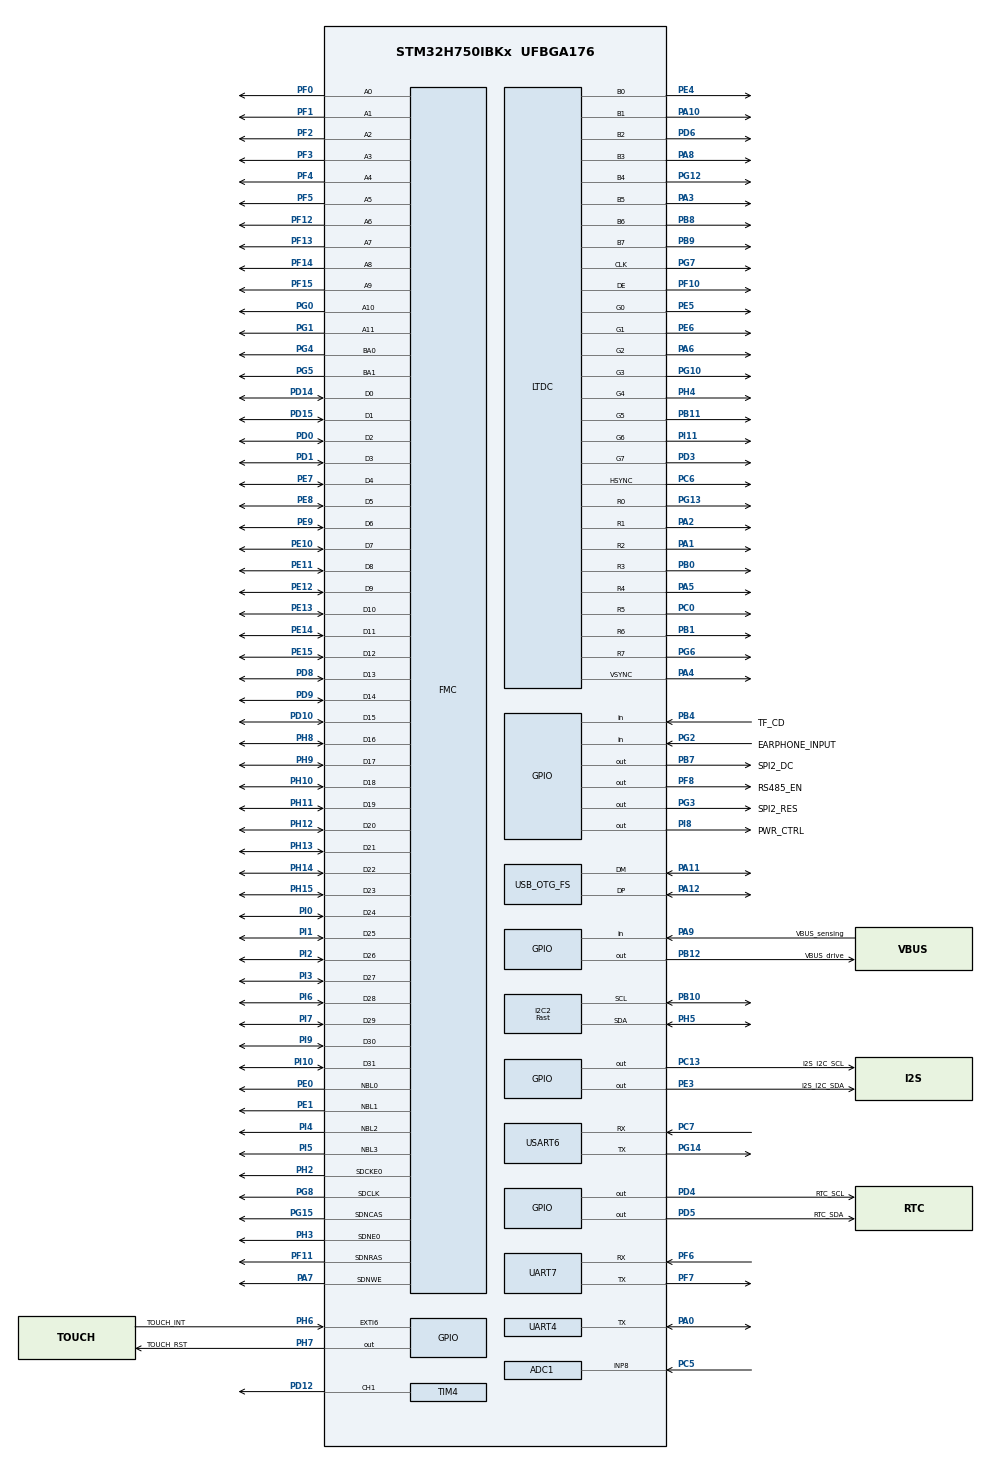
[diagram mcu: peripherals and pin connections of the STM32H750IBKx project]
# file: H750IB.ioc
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ADC1.Channel-3\#ChannelRegularConversion=ADC_CHANNEL_8
ADC1.ClockPrescaler=ADC_CLOCK_ASYNC_DIV8
ADC1.ContinuousConvMode=ENABLE
ADC1.ConversionDataManagement=ADC_CONVERSIONDATA_DMA_CIRCULAR
ADC1.ExternalTrigConv=ADC_EXTERNALTRIG_T15_TRGO
ADC1.NbrOfConversionFlag=1
ADC1.OffsetNumber-3\#ChannelRegularConversion=ADC_OFFSET_NONE
ADC1.OffsetSignedSaturation-3\#ChannelRegularConversion=DISABLE
ADC1.Overrun=ADC_OVR_DATA_OVERWRITTEN
ADC1.Rank-3\#ChannelRegularConversion=1
ADC1.SamplingTime-3\#ChannelRegularConversion=ADC_SAMPLETIME_387CYCLES_5
ADC1.master=1
ADC3.Channel-0\#ChannelRegularConversion=ADC_CHANNEL_TEMPSENSOR
ADC3.ClockPrescaler=ADC_CLOCK_ASYNC_DIV8
ADC3.ClockPrescalerADC3=ADC_CLOCK_ASYNC_DIV128
ADC3.ContinuousConvMode=ENABLE
ADC3.ConversionDataManagement=ADC_CONVERSIONDATA_DMA_CIRCULAR
ADC3.ExternalTrigConv=ADC_EXTERNALTRIG_T15_TRGO
ADC3.NbrOfConversionFlag=1
ADC3.OffsetNumber-0\#ChannelRegularConversion=ADC_OFFSET_NONE
ADC3.OffsetSignedSaturation-0\#ChannelRegularConversion=DISABLE
ADC3.Overrun=ADC_OVR_DATA_OVERWRITTEN
ADC3.Rank-0\#ChannelRegularConversion=1
ADC3.SamplingTime-0\#ChannelRegularConversion=ADC_SAMPLETIME_64CYCLES_5
CORTEX_M7.AccessPermission_S-Cortex_Memory_Protection_Unit_Region1_Settings_S=MPU_REGION_FULL_ACCESS
CORTEX_M7.AccessPermission_Spec=MPU_REGION_FULL_ACCESS
CORTEX_M7.BaseAddress_S-Cortex_Memory_Protection_Unit_Region1_Settings_S=0x24000000
CORTEX_M7.BaseAddress_Spec=0x70000000
CORTEX_M7.CPU_DCache=Enabled
CORTEX_M7.CPU_ICache=Enabled
CORTEX_M7.DisableExec_Spec=MPU_INSTRUCTION_ACCESS_ENABLE
CORTEX_M7.Enable_S-Cortex_Memory_Protection_Unit_Region1_Settings_S=MPU_REGION_ENABLE
CORTEX_M7.IsCacheable_S-Cortex_Memory_Protection_Unit_Region1_Settings_S=MPU_ACCESS_CACHEABLE
CORTEX_M7.IsCacheable_Spec=MPU_ACCESS_CACHEABLE
CORTEX_M7.IsShareable_Spec=MPU_ACCESS_NOT_SHAREABLE
CORTEX_M7.Size_S-Cortex_Memory_Protection_Unit_Region1_Settings_S=MPU_REGION_SIZE_1MB
CORTEX_M7.Size_Spec=MPU_REGION_SIZE_256MB
CORTEX_M7.SubRegionDisable_S-Cortex_Memory_Protection_Unit_Region1_Settings_S=0x00
CORTEX_M7.SubRegionDisable_Spec=0x00
CORTEX_M7.default_mode_Activation=1
DMA2D.ColorMode=DMA2D_OUTPUT_RGB565
Dma.ADC1.5.Direction=DMA_PERIPH_TO_MEMORY
Dma.ADC1.5.EventEnable=DISABLE
Dma.ADC1.5.FIFOMode=DMA_FIFOMODE_DISABLE
Dma.ADC1.5.Instance=DMA1_Stream5
Dma.ADC1.5.MemDataAlignment=DMA_MDATAALIGN_HALFWORD
Dma.ADC1.5.MemInc=DMA_MINC_ENABLE
Dma.ADC1.5.Mode=DMA_CIRCULAR
Dma.ADC1.5.PeriphDataAlignment=DMA_PDATAALIGN_HALFWORD
Dma.ADC1.5.PeriphInc=DMA_PINC_DISABLE
Dma.ADC1.5.Polarity=HAL_DMAMUX_REQ_GEN_RISING
Dma.ADC1.5.Priority=DMA_PRIORITY_LOW
Dma.ADC1.5.RequestNumber=1
Dma.ADC1.5.SignalID=NONE
Dma.ADC1.5.SyncEnable=DISABLE
Dma.ADC1.5.SyncPolarity=HAL_DMAMUX_SYNC_NO_EVENT
Dma.ADC1.5.SyncRequestNumber=1
Dma.ADC1.5.SyncSignalID=NONE
Dma.ADC3.4.Direction=DMA_PERIPH_TO_MEMORY
Dma.ADC3.4.EventEnable=DISABLE
Dma.ADC3.4.FIFOMode=DMA_FIFOMODE_DISABLE
Dma.ADC3.4.Instance=DMA1_Stream0
Dma.ADC3.4.MemDataAlignment=DMA_MDATAALIGN_HALFWORD
Dma.ADC3.4.MemInc=DMA_MINC_ENABLE
Dma.ADC3.4.Mode=DMA_CIRCULAR
Dma.ADC3.4.PeriphDataAlignment=DMA_PDATAALIGN_HALFWORD
Dma.ADC3.4.PeriphInc=DMA_PINC_DISABLE
Dma.ADC3.4.Polarity=HAL_DMAMUX_REQ_GEN_RISING
Dma.ADC3.4.Priority=DMA_PRIORITY_LOW
Dma.ADC3.4.RequestNumber=1
Dma.ADC3.4.SignalID=NONE
Dma.ADC3.4.SyncEnable=DISABLE
Dma.ADC3.4.SyncPolarity=HAL_DMAMUX_SYNC_NO_EVENT
Dma.ADC3.4.SyncRequestNumber=1
Dma.ADC3.4.SyncSignalID=NONE
Dma.Request0=UART4_TX
Dma.Request1=UART4_RX
Dma.Request2=UART7_RX
Dma.Request3=UART7_TX
Dma.Request4=ADC3
Dma.Request5=ADC1
Dma.Request6=USART6_RX
Dma.Request7=USART6_TX
Dma.UART4_RX.1.Direction=DMA_PERIPH_TO_MEMORY
Dma.UART4_RX.1.EventEnable=DISABLE
Dma.UART4_RX.1.FIFOMode=DMA_FIFOMODE_DISABLE
Dma.UART4_RX.1.Instance=DMA1_Stream1
Dma.UART4_RX.1.MemDataAlignment=DMA_MDATAALIGN_BYTE
Dma.UART4_RX.1.MemInc=DMA_MINC_ENABLE
Dma.UART4_RX.1.Mode=DMA_NORMAL
Dma.UART4_RX.1.PeriphDataAlignment=DMA_PDATAALIGN_BYTE
Dma.UART4_RX.1.PeriphInc=DMA_PINC_DISABLE
Dma.UART4_RX.1.Polarity=HAL_DMAMUX_REQ_GEN_RISING
Dma.UART4_RX.1.Priority=DMA_PRIORITY_LOW
Dma.UART4_RX.1.RequestNumber=1
Dma.UART4_RX.1.SignalID=NONE
Dma.UART4_RX.1.SyncEnable=DISABLE
Dma.UART4_RX.1.SyncPolarity=HAL_DMAMUX_SYNC_NO_EVENT
Dma.UART4_RX.1.SyncRequestNumber=1
Dma.UART4_RX.1.SyncSignalID=NONE
Dma.UART4_TX.0.Direction=DMA_MEMORY_TO_PERIPH
Dma.UART4_TX.0.EventEnable=DISABLE
Dma.UART4_TX.0.FIFOMode=DMA_FIFOMODE_DISABLE
Dma.UART4_TX.0.Instance=DMA1_Stream4
Dma.UART4_TX.0.MemDataAlignment=DMA_MDATAALIGN_BYTE
Dma.UART4_TX.0.MemInc=DMA_MINC_ENABLE
Dma.UART4_TX.0.Mode=DMA_NORMAL
Dma.UART4_TX.0.PeriphDataAlignment=DMA_PDATAALIGN_BYTE
Dma.UART4_TX.0.PeriphInc=DMA_PINC_DISABLE
Dma.UART4_TX.0.Polarity=HAL_DMAMUX_REQ_GEN_RISING
Dma.UART4_TX.0.Priority=DMA_PRIORITY_LOW
Dma.UART4_TX.0.RequestNumber=1
Dma.UART4_TX.0.SignalID=NONE
Dma.UART4_TX.0.SyncEnable=DISABLE
Dma.UART4_TX.0.SyncPolarity=HAL_DMAMUX_SYNC_NO_EVENT
Dma.UART4_TX.0.SyncRequestNumber=1
Dma.UART4_TX.0.SyncSignalID=NONE
Dma.UART7_RX.2.Direction=DMA_PERIPH_TO_MEMORY
Dma.UART7_RX.2.EventEnable=DISABLE
Dma.UART7_RX.2.FIFOMode=DMA_FIFOMODE_DISABLE
Dma.UART7_RX.2.Instance=DMA1_Stream2
Dma.UART7_RX.2.MemDataAlignment=DMA_MDATAALIGN_BYTE
Dma.UART7_RX.2.MemInc=DMA_MINC_ENABLE
Dma.UART7_RX.2.Mode=DMA_NORMAL
Dma.UART7_RX.2.PeriphDataAlignment=DMA_PDATAALIGN_BYTE
Dma.UART7_RX.2.PeriphInc=DMA_PINC_DISABLE
Dma.UART7_RX.2.Polarity=HAL_DMAMUX_REQ_GEN_RISING
Dma.UART7_RX.2.Priority=DMA_PRIORITY_LOW
Dma.UART7_RX.2.RequestNumber=1
Dma.UART7_RX.2.SignalID=NONE
Dma.UART7_RX.2.SyncEnable=DISABLE
Dma.UART7_RX.2.SyncPolarity=HAL_DMAMUX_SYNC_NO_EVENT
Dma.UART7_RX.2.SyncRequestNumber=1
Dma.UART7_RX.2.SyncSignalID=NONE
Dma.UART7_TX.3.Direction=DMA_MEMORY_TO_PERIPH
Dma.UART7_TX.3.EventEnable=DISABLE
Dma.UART7_TX.3.FIFOMode=DMA_FIFOMODE_DISABLE
Dma.UART7_TX.3.Instance=DMA1_Stream3
Dma.UART7_TX.3.MemDataAlignment=DMA_MDATAALIGN_BYTE
Dma.UART7_TX.3.MemInc=DMA_MINC_ENABLE
Dma.UART7_TX.3.Mode=DMA_NORMAL
Dma.UART7_TX.3.PeriphDataAlignment=DMA_PDATAALIGN_BYTE
Dma.UART7_TX.3.PeriphInc=DMA_PINC_DISABLE
Dma.UART7_TX.3.Polarity=HAL_DMAMUX_REQ_GEN_RISING
Dma.UART7_TX.3.Priority=DMA_PRIORITY_LOW
Dma.UART7_TX.3.RequestNumber=1
Dma.UART7_TX.3.SignalID=NONE
Dma.UART7_TX.3.SyncEnable=DISABLE
Dma.UART7_TX.3.SyncPolarity=HAL_DMAMUX_SYNC_NO_EVENT
Dma.UART7_TX.3.SyncRequestNumber=1
Dma.UART7_TX.3.SyncSignalID=NONE
Dma.USART6_RX.6.Direction=DMA_PERIPH_TO_MEMORY
Dma.USART6_RX.6.EventEnable=DISABLE
Dma.USART6_RX.6.FIFOMode=DMA_FIFOMODE_DISABLE
Dma.USART6_RX.6.Instance=DMA1_Stream6
Dma.USART6_RX.6.MemDataAlignment=DMA_MDATAALIGN_BYTE
Dma.USART6_RX.6.MemInc=DMA_MINC_ENABLE
Dma.USART6_RX.6.Mode=DMA_CIRCULAR
Dma.USART6_RX.6.PeriphDataAlignment=DMA_PDATAALIGN_BYTE
Dma.USART6_RX.6.PeriphInc=DMA_PINC_DISABLE
Dma.USART6_RX.6.Polarity=HAL_DMAMUX_REQ_GEN_RISING
Dma.USART6_RX.6.Priority=DMA_PRIORITY_LOW
Dma.USART6_RX.6.RequestNumber=1
Dma.USART6_RX.6.SignalID=NONE
Dma.USART6_RX.6.SyncEnable=DISABLE
Dma.USART6_RX.6.SyncPolarity=HAL_DMAMUX_SYNC_NO_EVENT
Dma.USART6_RX.6.SyncRequestNumber=1
Dma.USART6_RX.6.SyncSignalID=NONE
Dma.USART6_TX.7.Direction=DMA_MEMORY_TO_PERIPH
Dma.USART6_TX.7.EventEnable=DISABLE
Dma.USART6_TX.7.FIFOMode=DMA_FIFOMODE_DISABLE
Dma.USART6_TX.7.Instance=DMA1_Stream7
Dma.USART6_TX.7.MemDataAlignment=DMA_MDATAALIGN_BYTE
Dma.USART6_TX.7.MemInc=DMA_MINC_ENABLE
Dma.USART6_TX.7.Mode=DMA_NORMAL
Dma.USART6_TX.7.PeriphDataAlignment=DMA_PDATAALIGN_BYTE
Dma.USART6_TX.7.PeriphInc=DMA_PINC_DISABLE
Dma.USART6_TX.7.Polarity=HAL_DMAMUX_REQ_GEN_RISING
Dma.USART6_TX.7.Priority=DMA_PRIORITY_LOW
Dma.USART6_TX.7.RequestNumber=1
Dma.USART6_TX.7.SignalID=NONE
Dma.USART6_TX.7.SyncEnable=DISABLE
Dma.USART6_TX.7.SyncPolarity=HAL_DMAMUX_SYNC_NO_EVENT
Dma.USART6_TX.7.SyncRequestNumber=1
Dma.USART6_TX.7.SyncSignalID=NONE
FMC.CASLatency1=FMC_SDRAM_CAS_LATENCY_3
FMC.ColumnBitsNumber1=FMC_SDRAM_COLUMN_BITS_NUM_9
FMC.ExitSelfRefreshDelay1=7
FMC.LoadToActiveDelay1=2
FMC.RCDDelay1=2
FMC.RPDelay1=2
FMC.RPDelay2=2
FMC.ReadBurst1=FMC_SDRAM_RBURST_ENABLE
FMC.ReadBurst2=FMC_SDRAM_RBURST_ENABLE
FMC.ReadPipeDelay1=FMC_SDRAM_RPIPE_DELAY_1
FMC.ReadPipeDelay2=FMC_SDRAM_RPIPE_DELAY_1
FMC.RowCycleDelay1=7
FMC.RowCycleDelay2=7
FMC.SDClockPeriod1=FMC_SDRAM_CLOCK_PERIOD_2
FMC.SDClockPeriod2=FMC_SDRAM_CLOCK_PERIOD_2
FMC.SelfRefreshTime1=4
FMC.WriteRecoveryTime1=3
I2C2.I2C_Speed_Mode=I2C_Fast
I2C2.Timing=0x00B03FDB
LTDC.ActiveH=600
LTDC.ActiveW=1024
LTDC.Alpha_L0=255
LTDC.FBStartAdress_L0=0x70000000
LTDC.HBP=140
LTDC.HFP=160
LTDC.HSync=20
LTDC.ImageHeight_L0=600
LTDC.ImageWidth_L0=1024
LTDC.Layers=0
LTDC.PixelFormat_L0=LTDC_PIXEL_FORMAT_RGB888
LTDC.VBP=20
LTDC.VFP=12
LTDC.VSync=3
LTDC.WindowX1_L0=1024
LTDC.WindowY1_L0=600
Mcu.Family=STM32H7
Mcu.Name=STM32H750IBKx
Mcu.Package=UFBGA176
Mcu.UserConstants=SysTemp_TIM,$$_TIM15_IP_HANDLE_$$;VBAT_ADC,$$_ADC1_IP_HANDLE_$$;ESP_UART,$$_USART6_IP_HANDLE_$$
NVIC.DMA1_Stream0_IRQn=true\:0\:0\:false\:false\:true\:false\:true\:true
NVIC.DMA1_Stream1_IRQn=true\:0\:0\:false\:false\:true\:false\:true\:true
NVIC.DMA1_Stream2_IRQn=true\:0\:0\:false\:false\:true\:false\:true\:true
NVIC.DMA1_Stream3_IRQn=true\:0\:0\:false\:false\:true\:false\:true\:true
NVIC.DMA1_Stream4_IRQn=true\:0\:0\:false\:false\:true\:false\:true\:true
NVIC.DMA1_Stream5_IRQn=true\:0\:0\:false\:false\:true\:false\:true\:true
NVIC.DMA1_Stream6_IRQn=true\:0\:0\:false\:false\:true\:false\:true\:true
NVIC.DMA1_Stream7_IRQn=true\:0\:0\:false\:false\:true\:false\:true\:true
NVIC.EXTI9_5_IRQn=true\:0\:0\:false\:false\:true\:true\:true\:true
NVIC.I2C2_ER_IRQn=true\:0\:0\:false\:false\:true\:true\:true\:true
NVIC.I2C2_EV_IRQn=true\:0\:0\:false\:false\:true\:true\:true\:true
NVIC.OTG_FS_IRQn=true\:0\:0\:false\:false\:true\:false\:true\:true
NVIC.PriorityGroup=NVIC_PRIORITYGROUP_4
NVIC.TIM8_TRG_COM_TIM14_IRQn=true\:0\:0\:false\:false\:true\:true\:true\:true
NVIC.UART4_IRQn=true\:0\:0\:false\:false\:true\:true\:true\:true
NVIC.UART7_IRQn=true\:0\:0\:false\:false\:true\:true\:true\:true
NVIC.USART6_IRQn=true\:0\:0\:false\:false\:true\:true\:true\:true
PA0.GPIO_PuPd=GPIO_PULLUP
PA0.Mode=Half_duplex(single_wire_mode)
PA0.Signal=UART4_TX
PA1.GPIO_Speed=GPIO_SPEED_FREQ_HIGH
PA1.Mode=RGB888
PA1.Signal=LTDC_R2
PA10.GPIO_Speed=GPIO_SPEED_FREQ_HIGH
PA10.Mode=RGB888
PA10.Signal=LTDC_B1
PA11.Mode=Device_Only
PA11.Signal=USB_OTG_FS_DM
PA12.Mode=Device_Only
PA12.Signal=USB_OTG_FS_DP
PA13\ (JTMS/SWDIO).Mode=Serial_Wire
PA13\ (JTMS/SWDIO).Signal=DEBUG_JTMS-SWDIO
PA14\ (JTCK/SWCLK).Mode=Serial_Wire
PA14\ (JTCK/SWCLK).Signal=DEBUG_JTCK-SWCLK
PA2.GPIO_Speed=GPIO_SPEED_FREQ_HIGH
PA2.Mode=RGB888
PA2.Signal=LTDC_R1
PA3.GPIO_Speed=GPIO_SPEED_FREQ_HIGH
PA3.Mode=RGB888
PA3.Signal=LTDC_B5
PA4.GPIO_Speed=GPIO_SPEED_FREQ_HIGH
PA4.Mode=RGB888
PA4.Signal=LTDC_VSYNC
PA5.GPIO_Speed=GPIO_SPEED_FREQ_HIGH
PA5.Mode=RGB888
PA5.Signal=LTDC_R4
PA6.GPIO_Speed=GPIO_SPEED_FREQ_HIGH
PA6.Mode=RGB888
PA6.Signal=LTDC_G2
PA7.Signal=FMC_SDNWE
PA8.GPIO_Speed=GPIO_SPEED_FREQ_HIGH
PA8.Mode=RGB888
PA8.Signal=LTDC_B3
PA9.GPIO_Label=VBUS_sensing
PA9.Signal=GPIO_Input
PB0.GPIO_Speed=GPIO_SPEED_FREQ_HIGH
PB0.Mode=RGB888
PB0.Signal=LTDC_R3
PB1.GPIO_Speed=GPIO_SPEED_FREQ_HIGH
PB1.Mode=RGB888
PB1.Signal=LTDC_R6
PB10.GPIO_Pu=GPIO_PULLUP
PB10.Mode=I2C
PB10.Signal=I2C2_SCL
PB11.GPIO_Speed=GPIO_SPEED_FREQ_HIGH
PB11.Mode=RGB888
PB11.Signal=LTDC_G5
PB12.GPIO_Label=VBUS_drive
PB12.Signal=GPIO_Output
PB4\ (NJTRST).GPIO_Label=TF_CD
PB4\ (NJTRST).Signal=GPIO_Input
PB7.GPIO_Label=SPI2_DC
PB7.Signal=GPIO_Output
PB8.GPIO_Speed=GPIO_SPEED_FREQ_HIGH
PB8.Mode=RGB888
PB8.Signal=LTDC_B6
PB9.GPIO_Speed=GPIO_SPEED_FREQ_HIGH
PB9.Mode=RGB888
PB9.Signal=LTDC_B7
PC0.GPIO_Speed=GPIO_SPEED_FREQ_HIGH
PC0.Mode=RGB888
PC0.Signal=LTDC_R5
PC13.GPIO_Label=I2S_I2C_SCL
PC13.Signal=GPIO_Output
PC14-OSC32_IN\ (OSC32_IN).Mode=LSE-External-Oscillator
PC14-OSC32_IN\ (OSC32_IN).Signal=RCC_OSC32_IN
PC15-OSC32_OUT\ (OSC32_OUT).Mode=LSE-External-Oscillator
PC15-OSC32_OUT\ (OSC32_OUT).Signal=RCC_OSC32_OUT
PC5.Signal=ADCx_INP8
PC6.GPIO_Speed=GPIO_SPEED_FREQ_HIGH
PC6.Mode=RGB888
PC6.Signal=LTDC_HSYNC
PC7.Mode=Asynchronous
PC7.Signal=USART6_RX
PD0.Signal=FMC_D2_DA2
PD1.Signal=FMC_D3_DA3
PD10.Signal=FMC_D15_DA15
PD12.GPIO_ModeDefaultPP=GPIO_MODE_AF_PP
PD12.GPIO_PuPd=GPIO_NOPULL
PD12.GPIO_Speed=GPIO_SPEED_FREQ_LOW
PD12.Signal=S_TIM4_CH1
PD14.Signal=FMC_D0_DA0
PD15.Signal=FMC_D1_DA1
PD3.GPIO_Speed=GPIO_SPEED_FREQ_HIGH
PD3.Mode=RGB888
PD3.Signal=LTDC_G7
PD4.GPIO_Label=RTC_SCL
PD4.GPIO_ModeDefaultOutputPP=GPIO_MODE_OUTPUT_OD
PD4.GPIO_PuPd=GPIO_NOPULL
PD4.Signal=GPIO_Output
PD5.GPIO_Label=RTC_SDA
PD5.GPIO_ModeDefaultOutputPP=GPIO_MODE_OUTPUT_OD
PD5.GPIO_PuPd=GPIO_NOPULL
PD5.Signal=GPIO_Output
PD6.GPIO_Speed=GPIO_SPEED_FREQ_HIGH
PD6.Mode=RGB888
PD6.Signal=LTDC_B2
PD8.Signal=FMC_D13_DA13
PD9.Signal=FMC_D14_DA14
PE0.Signal=FMC_NBL0
PE1.Signal=FMC_NBL1
PE10.Signal=FMC_D7_DA7
PE11.Signal=FMC_D8_DA8
PE12.Signal=FMC_D9_DA9
PE13.Signal=FMC_D10_DA10
PE14.Signal=FMC_D11_DA11
PE15.Signal=FMC_D12_DA12
PE3.GPIO_Label=I2S_I2C_SDA
PE3.Signal=GPIO_Output
PE4.GPIO_Speed=GPIO_SPEED_FREQ_HIGH
PE4.Mode=RGB888
PE4.Signal=LTDC_B0
PE5.GPIO_Speed=GPIO_SPEED_FREQ_HIGH
PE5.Mode=RGB888
PE5.Signal=LTDC_G0
PE6.GPIO_Speed=GPIO_SPEED_FREQ_HIGH
PE6.Mode=RGB888
PE6.Signal=LTDC_G1
PE7.Signal=FMC_D4_DA4
PE8.Signal=FMC_D5_DA5
PE9.Signal=FMC_D6_DA6
PF0.Signal=FMC_A0
PF1.Signal=FMC_A1
PF10.GPIO_Speed=GPIO_SPEED_FREQ_HIGH
PF10.Mode=RGB888
PF10.Signal=LTDC_DE
PF11.Signal=FMC_SDNRAS
PF12.Signal=FMC_A6
PF13.Signal=FMC_A7
PF14.Signal=FMC_A8
PF15.Signal=FMC_A9
PF2.Signal=FMC_A2
PF3.Signal=FMC_A3
PF4.Signal=FMC_A4
PF5.Signal=FMC_A5
PF6.Mode=Asynchronous
PF6.Signal=UART7_RX
PF7.Mode=Asynchronous
PF7.Signal=UART7_TX
PF8.GPIO_Label=RS485_EN
PF8.Signal=GPIO_Output
PG0.Signal=FMC_A10
PG1.Signal=FMC_A11
PG10.GPIO_Speed=GPIO_SPEED_FREQ_HIGH
PG10.Mode=RGB888
PG10.Signal=LTDC_G3
PG12.GPIO_Speed=GPIO_SPEED_FREQ_HIGH
PG12.Mode=RGB888
PG12.Signal=LTDC_B4
PG13.GPIO_Speed=GPIO_SPEED_FREQ_HIGH
PG13.Mode=RGB888
PG13.Signal=LTDC_R0
PG14.Mode=Asynchronous
PG14.Signal=USART6_TX
PG15.Signal=FMC_SDNCAS
PG2.GPIO_Label=EARPHONE_INPUT
PG2.Signal=GPIO_Input
PG3.GPIO_Label=SPI2_RES
PG3.Signal=GPIO_Output
PG4.Signal=FMC_A14_BA0
PG5.Signal=FMC_A15_BA1
PG6.GPIO_Speed=GPIO_SPEED_FREQ_HIGH
PG6.Mode=RGB888
PG6.Signal=LTDC_R7
PG7.GPIO_Speed=GPIO_SPEED_FREQ_HIGH
PG7.Mode=RGB888
PG7.Signal=LTDC_CLK
PG8.Signal=FMC_SDCLK
PH0-OSC_IN\ (PH0).Mode=HSE-External-Oscillator
PH0-OSC_IN\ (PH0).Signal=RCC_OSC_IN
PH1-OSC_OUT\ (PH1).Mode=HSE-External-Oscillator
PH1-OSC_OUT\ (PH1).Signal=RCC_OSC_OUT
PH10.Signal=FMC_D18
PH11.Signal=FMC_D19
PH12.Signal=FMC_D20
PH13.Signal=FMC_D21
PH14.Signal=FMC_D22
PH15.Signal=FMC_D23
PH2.Mode=SdramChipSelect1_1
PH2.Signal=FMC_SDCKE0
PH3.Mode=SdramChipSelect1_1
PH3.Signal=FMC_SDNE0
PH4.GPIO_Speed=GPIO_SPEED_FREQ_HIGH
PH4.Mode=RGB888
PH4.Signal=LTDC_G4
PH5.GPIO_Pu=GPIO_PULLUP
PH5.Mode=I2C
PH5.Signal=I2C2_SDA
PH6.GPIO_Label=TOUCH_INT
PH6.GPIO_PuPd=GPIO_PULLDOWN
PH6.Signal=GPXTI6
PH7.GPIO_Label=TOUCH_RST
PH7.Signal=GPIO_Output
PH8.Signal=FMC_D16
PH9.Signal=FMC_D17
PI0.Signal=FMC_D24
PI1.Signal=FMC_D25
PI10.Signal=FMC_D31
PI11.GPIO_Speed=GPIO_SPEED_FREQ_HIGH
PI11.Mode=RGB888
PI11.Signal=LTDC_G6
PI2.Signal=FMC_D26
PI3.Signal=FMC_D27
PI4.Signal=FMC_NBL2
PI5.Signal=FMC_NBL3
PI6.Signal=FMC_D28
PI7.Signal=FMC_D29
PI8.GPIO_Label=PWR_CTRL
PI8.Signal=GPIO_Output
PI9.Signal=FMC_D30
ProjectManager.HeapSize=0x1400
ProjectManager.StackSize=0x400
ProjectManager.TargetToolchain=MDK-ARM V5.32
RCC.ADCFreq_Value=60000000
RCC.APB1Freq_Value=120000000
RCC.APB2Freq_Value=120000000
RCC.APB3Freq_Value=120000000
RCC.APB4Freq_Value=120000000
RCC.CortexFreq_Value=480000000
RCC.D1PPRE=RCC_APB3_DIV2
RCC.D2PPRE1=RCC_APB1_DIV2
RCC.D2PPRE2=RCC_APB2_DIV2
RCC.D3PPRE=RCC_APB4_DIV2
RCC.DIVM1=3
RCC.DIVM2=12
RCC.DIVM3=24
RCC.DIVN1=120
RCC.DIVN2=120
RCC.DIVN3=330
RCC.DIVP2=4
RCC.DIVQ1=20
RCC.DIVR2=1
RCC.DIVR3=10
RCC.FMCCLockSelection=RCC_FMCCLKSOURCE_PLL2
RCC.HCLKFreq_Value=240000000
RCC.HPRE=RCC_HCLK_DIV2
RCC.HSE_VALUE=24000000
RCC.PLL2FRACN=0
RCC.PLL3FRACN=0
RCC.PLLFRACN=0
RCC.PLLSourceVirtual=RCC_PLLSOURCE_HSE
RCC.PWR_Regulator_Voltage_Scale=PWR_REGULATOR_VOLTAGE_SCALE0
RCC.ProductRev=revV
RCC.RTCClockSelection=RCC_RTCCLKSOURCE_LSE
RCC.SYSCLKFreq_VALUE=480000000
RCC.SYSCLKSource=RCC_SYSCLKSOURCE_PLLCLK
RCC.USBFreq_Value=48000000
SH.ADCx_INP8.0=ADC1_INP8,IN8-Single-Ended
SH.FMC_A0.0=FMC_A0,12b-sda1
SH.FMC_A1.0=FMC_A1,12b-sda1
SH.FMC_A10.0=FMC_A10,12b-sda1
SH.FMC_A11.0=FMC_A11,12b-sda1
SH.FMC_A14_BA0.0=FMC_BA0,FourSdramBanks1
SH.FMC_A15_BA1.0=FMC_BA1,FourSdramBanks1
SH.FMC_A2.0=FMC_A2,12b-sda1
SH.FMC_A3.0=FMC_A3,12b-sda1
SH.FMC_A4.0=FMC_A4,12b-sda1
SH.FMC_A5.0=FMC_A5,12b-sda1
SH.FMC_A6.0=FMC_A6,12b-sda1
SH.FMC_A7.0=FMC_A7,12b-sda1
SH.FMC_A8.0=FMC_A8,12b-sda1
SH.FMC_A9.0=FMC_A9,12b-sda1
SH.FMC_D0_DA0.0=FMC_D0,sd-32b-d1
SH.FMC_D10_DA10.0=FMC_D10,sd-32b-d1
SH.FMC_D11_DA11.0=FMC_D11,sd-32b-d1
SH.FMC_D12_DA12.0=FMC_D12,sd-32b-d1
SH.FMC_D13_DA13.0=FMC_D13,sd-32b-d1
SH.FMC_D14_DA14.0=FMC_D14,sd-32b-d1
SH.FMC_D15_DA15.0=FMC_D15,sd-32b-d1
SH.FMC_D16.0=FMC_D16,sd-32b-d1
SH.FMC_D17.0=FMC_D17,sd-32b-d1
SH.FMC_D18.0=FMC_D18,sd-32b-d1
SH.FMC_D19.0=FMC_D19,sd-32b-d1
SH.FMC_D1_DA1.0=FMC_D1,sd-32b-d1
SH.FMC_D20.0=FMC_D20,sd-32b-d1
SH.FMC_D21.0=FMC_D21,sd-32b-d1
SH.FMC_D22.0=FMC_D22,sd-32b-d1
SH.FMC_D23.0=FMC_D23,sd-32b-d1
SH.FMC_D24.0=FMC_D24,sd-32b-d1
SH.FMC_D25.0=FMC_D25,sd-32b-d1
SH.FMC_D26.0=FMC_D26,sd-32b-d1
SH.FMC_D27.0=FMC_D27,sd-32b-d1
SH.FMC_D28.0=FMC_D28,sd-32b-d1
SH.FMC_D29.0=FMC_D29,sd-32b-d1
SH.FMC_D2_DA2.0=FMC_D2,sd-32b-d1
SH.FMC_D30.0=FMC_D30,sd-32b-d1
SH.FMC_D31.0=FMC_D31,sd-32b-d1
SH.FMC_D3_DA3.0=FMC_D3,sd-32b-d1
SH.FMC_D4_DA4.0=FMC_D4,sd-32b-d1
SH.FMC_D5_DA5.0=FMC_D5,sd-32b-d1
SH.FMC_D6_DA6.0=FMC_D6,sd-32b-d1
SH.FMC_D7_DA7.0=FMC_D7,sd-32b-d1
SH.FMC_D8_DA8.0=FMC_D8,sd-32b-d1
SH.FMC_D9_DA9.0=FMC_D9,sd-32b-d1
SH.FMC_NBL0.0=FMC_NBL0,Sd4ByteEnable1
SH.FMC_NBL1.0=FMC_NBL1,Sd4ByteEnable1
SH.FMC_NBL2.0=FMC_NBL2,Sd4ByteEnable1
SH.FMC_NBL3.0=FMC_NBL3,Sd4ByteEnable1
SH.FMC_SDCLK.0=FMC_SDCLK,12b-sda1
SH.FMC_SDNCAS.0=FMC_SDNCAS,12b-sda1
SH.FMC_SDNRAS.0=FMC_SDNRAS,12b-sda1
SH.FMC_SDNWE.0=FMC_SDNWE,12b-sda1
SH.S_TIM4_CH1.0=TIM4_CH1,PWM Generation1 CH1
TIM14.Period=1000
TIM14.Prescaler=240-1
TIM15.Period=100
TIM15.Prescaler=24000-1
TIM15.TIM_MasterOutputTrigger=TIM_TRGO_UPDATE
TIM4.Channel-PWM\ Generation1\ CH1=TIM_CHANNEL_1
TIM4.Period=10000
TIM4.Prescaler=0
UART4.BaudRate=250000
UART4.FIFOMode=FIFOMODE_DISABLE
UART4.StopBits=UART_STOPBITS_2
UART4.SwapParam=UART_ADVFEATURE_SWAP_DISABLE
USART6.OverrunDisableParam=ADVFEATURE_OVERRUN_ENABLE
USART6.VirtualMode-Asynchronous=VM_ASYNC
USB_DEVICE.CLASS_NAME_FS=CDC
USB_DEVICE.VirtualMode-CDC_FS=Cdc
USB_DEVICE.VirtualModeFS=Cdc_FS
USB_OTG_FS.VirtualMode=Device_Only
VP_ADC3_TempSens_Input.Mode=IN-TempSens
VP_DMA2D_VS_DMA2D.Mode=DMA2D_Activate
VP_RTC_VS_RTC_Activate.Mode=RTC_Enabled
VP_RTC_VS_RTC_Calendar.Mode=RTC_Calendar
VP_TIM14_VS_ClockSourceINT.Mode=Enable_Timer
VP_TIM15_VS_ClockSourceINT.Mode=Internal
VP_USB_DEVICE_VS_USB_DEVICE_CDC_FS.Mode=CDC_FS
board=custom

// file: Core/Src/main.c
/* USER CODE BEGIN Header */
/**
 ******************************************************************************
 * @file           : main.c
 * @brief          : Main program body
 ******************************************************************************
 * @attention
 *
 * Copyright (c) 2023 STMicroelectronics.
 * All rights reserved.
 *
 * This software is licensed under terms that can be found in the LICENSE file
 * in the root directory of this software component.
 * If no LICENSE file comes with this software, it is provided AS-IS.
 *
 ******************************************************************************
 */
/* USER CODE END Header */
#include "main.h"
#include "adc.h"
#include "dma.h"
#include "dma2d.h"
#include "i2c.h"
#include "ltdc.h"
#include "rtc.h"
#include "tim.h"
#include "usart.h"
#include "usb_device.h"
#include "gpio.h"
#include "fmc.h"

/* USER CODE BEGIN Includes */
#include "usbd_cdc_if.h"
#include "FT5436.h"
#include "GT9xx.h"
#include "lvgl.h"
#include "lv_conf.h"
#include "lv_port_disp_template.h"
#include "lv_port_indev_template.h"
// #include "lv_demos.h"
#include "mylvgl.h"
#include "RS485.h"
#include "DMX.h"
#include "SysTemp.h"
#include "stc.h"
#include "RTC_SD3078.h"
#include "Vofa+.h"

#include "stdlib.h"
/* USER CODE END Includes */

/* USER CODE BEGIN PM */
int fputc(int ch, FILE *f)
{
  HAL_UART_Transmit(&huart7, (uint8_t *)&ch, 1, 10); // ?¤??????????????
  return (ch);
}
// #define SDRAM_Size 16*1024*1024  //16M字节
#define SDRAM_Size 32 * 1024 * 1024 // 32M字节
#define SDRAM_BANK_ADDR (0x70000000)
/******************************************************************************************************
 *	函 数 名: SDRAM_Test
 *	入口参数: 无
 *	返 回 值: SUCCESS - 成功，ERROR - 失败
 *	函数功能: SDRAM测试
 *	说    明: 先以16位的数据宽度写入数据，再读取出来一一进行比较，随后以8位的数据宽度写入，
 *				 用以验证NBL0和NBL1两个引脚的连接是否正常。
 *******************************************************************************************************/

uint8_t SDRAM_Test(void)
{
  uint32_t i = 0;        // 计数变量
  uint32_t ReadData = 0; // 读取到的数据
  uint8_t ReadData_8b;

  uint32_t ExecutionTime_Begin; // 开始时间
  uint32_t ExecutionTime_End;   // 结束时间
  uint32_t ExecutionTime;       // 执行时间
  float ExecutionSpeed;         // 执行速度

  usb_printf("\r\n*****************************************************************************************************\r\n");
  HAL_Delay(1);
  usb_printf("\r\n进行速度测试>>>\r\n");
  HAL_Delay(1);

  // 写入 >>>>>>>>>>>>>>>>>>>>>>>>>>>>>>>>>>>>>>>>>>>>>>>>>>>>>>>>>>>>>>>>>>>>>>>>>>>>>>>>>>>>>>

  ExecutionTime_Begin = HAL_GetTick(); // 获取 systick 当前时间，单位ms

  for (i = 0; i < SDRAM_Size / 4; i++)
  {
    *(__IO uint32_t *)(SDRAM_BANK_ADDR + 4 * i) = (uint32_t)i; // 写入数据
  }
  ExecutionTime_End = HAL_GetTick();                                       // 获取 systick 当前时间，单位ms
  ExecutionTime = ExecutionTime_End - ExecutionTime_Begin;                 // 计算擦除时间，单位ms
  ExecutionSpeed = (float)SDRAM_Size / 1024 / 1024 / ExecutionTime * 1000; // 计算速度，单位 MB/S

  usb_printf("\r\n以32位数据宽度写入数据，大小：%d MB，耗时: %d ms, 写入速度：%.2f MB/s\r\n", SDRAM_Size / 1024 / 1024, ExecutionTime, ExecutionSpeed);
  HAL_Delay(1);

  // 读取	>>>>>>>>>>>>>>>>>>>>>>>>>>>>>>>>>>>>>>>>>>>>>>>>>>>>>>>>>>>>>>>>>>>>>>>>>>>>>>>>>>>>>>

  ExecutionTime_Begin = HAL_GetTick(); // 获取 systick 当前时间，单位ms

  for (i = 0; i < SDRAM_Size / 4; i++)
  {
    ReadData = *(__IO uint32_t *)(SDRAM_BANK_ADDR + 4 * i); // 从SDRAM读出数据
  }
  ExecutionTime_End = HAL_GetTick();                                       // 获取 systick 当前时间，单位ms
  ExecutionTime = ExecutionTime_End - ExecutionTime_Begin;                 // 计算擦除时间，单位ms
  ExecutionSpeed = (float)SDRAM_Size / 1024 / 1024 / ExecutionTime * 1000; // 计算速度，单位 MB/S

  usb_printf("\r\n读取数据完毕，大小：%d MB，耗时: %d ms, 读取速度：%.2f MB/s\r\n", SDRAM_Size / 1024 / 1024, ExecutionTime, ExecutionSpeed);
  HAL_Delay(1);

  // 数据校验 >>>>>>>>>>>>>>>>>>>>>>>>>>>>>>>>>>>>>>>>>>>>>>>>>>>>>>>>>>>>>>>>>>>>>>>>>>>>>>>>>>>>>>

  usb_printf("\r\n*****************************************************************************************************\r\n");
  HAL_Delay(1);
  usb_printf("\r\n进行数据校验>>>\r\n");
  HAL_Delay(1);

  for (i = 0; i < SDRAM_Size / 4; i++)
  {
    ReadData = *(__IO uint32_t *)(SDRAM_BANK_ADDR + 4 * i); // 从SDRAM读出数据
    if (ReadData != (uint32_t)i)                            // 检测数据，若不相等，跳出函数,返回检测失败结果。
    {
      usb_printf("\r\nSDRAM测试失败！！\r\n");
      HAL_Delay(1);
      return ERROR; // 返回失败标志
    }
  }

  usb_printf("\r\n32位数据宽度读写通过，以8位数据宽度写入数据\r\n");
  HAL_Delay(1);
  for (i = 0; i < 255; i++)
  {
    *(__IO uint8_t *)(SDRAM_BANK_ADDR + i) = (uint8_t)i;
  }
  usb_printf("写入完毕，读取数据并比较...\r\n");
  HAL_Delay(1);
  for (i = 0; i < 255; i++)
  {
    ReadData_8b = *(__IO uint8_t *)(SDRAM_BANK_ADDR + i);
    if (ReadData_8b != (uint8_t)i) // 检测数据，若不相等，跳出函数,返回检测失败结果。
    {
      usb_printf("8位数据宽度读写测试失败！！\r\n");
      HAL_Delay(1);
      usb_printf("请检查NBL0和NBL1的连接\r\n");
      HAL_Delay(1);
      return ERROR; // 返回失败标志
    }
  }
  usb_printf("8位数据宽度读写通过\r\n");
  HAL_Delay(1);
  usb_printf("SDRAM读写测试通过，系统正常\r\n");
  HAL_Delay(1);
  return SUCCESS; // 返回成功标志
}

/* USER CODE END PM */

void SystemClock_Config(void);
void PeriphCommonClock_Config(void);
static void MPU_Initialize(void);
static void MPU_Config(void);

/* USER CODE BEGIN 0 */

extern touchPoint POINT1;
/* USER CODE END 0 */

int main(void)
{
  /* USER CODE BEGIN 1 */
  SCB->VTOR = 0x08020000;
  __enable_irq();

  /* USER CODE END 1 */

  /* Enable I-Cache---------------------------------------------------------*/
  SCB_EnableICache();

  /* Enable D-Cache---------------------------------------------------------*/
  SCB_EnableDCache();

  /* MCU Configuration--------------------------------------------------------*/

  /* Reset of all peripherals, Initializes the Flash interface and the Systick. */
  HAL_Init();

  /* MPU Configuration--------------------------------------------------------*/
  MPU_Config();

  /* Configure the system clock */
  SystemClock_Config();

  /* Configure the peripherals common clocks */
  PeriphCommonClock_Config();

  /* Initialize all configured peripherals */
  MX_GPIO_Init();
  MX_DMA_Init();
  MX_UART7_Init();
  MX_I2C2_Init();
  MX_TIM4_Init();
  MX_USB_DEVICE_Init();
  MX_DMA2D_Init();
  MX_FMC_Init();
  //  while (1)
  //  {
  //    SDRAM_Test();
  //  }
  MX_LTDC_Init();
  MX_TIM14_Init();
  MX_ADC3_Init();
  MX_TIM15_Init();
  MX_UART4_Init();
  MX_RTC_Init();
  MX_ADC1_Init();
  MX_USART6_UART_Init();
  /* USER CODE BEGIN 2 */
  // HAL_Delay(100);
  /*??启SysTemp和VBAT转换*/
  SysTemp_Start_Conv();

  TOUCH_INIT();
  Touch_I2C_READTouch(touch_points);
  lv_init();
  lv_port_disp_init();
  // lv_disp_set_rotation(NULL, LV_DISP_ROT_NONE);
  lv_port_indev_init();
  mylv_DMX_Controller();
  // lv_demo_music();
  //  lv_demo_widgets();
  // lv_demo_benchmark();
  lv_task_handler();

  HAL_UARTEx_ReceiveToIdle_DMA(&ESP_UART, uart7_buf, UART7_MAX_BUF);

  HAL_TIM_PWM_Start(&htim4, TIM_CHANNEL_1);
  HAL_Delay(50);
  for (uint16_t i = 0; i < 0x3F; i++)
  {
    BL_change(i);
    HAL_Delay(1);
  }
  DMX_Init(&htim14);
  HAL_TIM_Base_Start_IT(&htim14);
  Vofa_Fdata_Init();

  /* USER CODE END 2 */

  /* Infinite loop */
  /* USER CODE BEGIN WHILE */
  while (1)
  {
    static uint16_t count = 0;
    lv_task_handler();
    HAL_Delay(20);
    lv_timer_handler();
    Vofa_CH_SEND();
    // HAL_ADC_Start(&hadc1);
    // HAL_ADC_PollForConversion(&hadc1, 10);
    // float vbat = (float)HAL_ADC_GetValue(&hadc1) / 0xFFFF * 3.3 * 2;
    // USB_Transmit_Printf("BAT Voltage: %0.3f", vbat);

    /* USER CODE END WHILE */

  }
}

void SystemClock_Config(void)
{
  RCC_OscInitTypeDef RCC_OscInitStruct = {0};
  RCC_ClkInitTypeDef RCC_ClkInitStruct = {0};

  /** Supply configuration update enable
   */
  HAL_PWREx_ConfigSupply(PWR_LDO_SUPPLY);

  /** Configure the main internal regulator output voltage
   */
  __HAL_PWR_VOLTAGESCALING_CONFIG(PWR_REGULATOR_VOLTAGE_SCALE1);

  while (!__HAL_PWR_GET_FLAG(PWR_FLAG_VOSRDY))
  {
  }

  __HAL_RCC_SYSCFG_CLK_ENABLE();
  __HAL_PWR_VOLTAGESCALING_CONFIG(PWR_REGULATOR_VOLTAGE_SCALE0);

  while (!__HAL_PWR_GET_FLAG(PWR_FLAG_VOSRDY))
  {
  }

  /** Configure LSE Drive Capability
   */
  HAL_PWR_EnableBkUpAccess();
  __HAL_RCC_LSEDRIVE_CONFIG(RCC_LSEDRIVE_LOW);

  /** Initializes the RCC Oscillators according to the specified parameters
   * in the RCC_OscInitTypeDef structure.
   */
  RCC_OscInitStruct.OscillatorType = RCC_OSCILLATORTYPE_HSE | RCC_OSCILLATORTYPE_LSE;
  RCC_OscInitStruct.HSEState = RCC_HSE_ON;
  RCC_OscInitStruct.LSEState = RCC_LSE_ON;
  RCC_OscInitStruct.PLL.PLLState = RCC_PLL_ON;
  RCC_OscInitStruct.PLL.PLLSource = RCC_PLLSOURCE_HSE;
  RCC_OscInitStruct.PLL.PLLM = 3;
  RCC_OscInitStruct.PLL.PLLN = 120;
  RCC_OscInitStruct.PLL.PLLP = 2;
  RCC_OscInitStruct.PLL.PLLQ = 20;
  RCC_OscInitStruct.PLL.PLLR = 2;
  RCC_OscInitStruct.PLL.PLLRGE = RCC_PLL1VCIRANGE_3;
  RCC_OscInitStruct.PLL.PLLVCOSEL = RCC_PLL1VCOWIDE;
  RCC_OscInitStruct.PLL.PLLFRACN = 0;
  if (HAL_RCC_OscConfig(&RCC_OscInitStruct) != HAL_OK)
  {
    Error_Handler();
  }

  /** Initializes the CPU, AHB and APB buses clocks
   */
  RCC_ClkInitStruct.ClockType = RCC_CLOCKTYPE_HCLK | RCC_CLOCKTYPE_SYSCLK | RCC_CLOCKTYPE_PCLK1 | RCC_CLOCKTYPE_PCLK2 | RCC_CLOCKTYPE_D3PCLK1 | RCC_CLOCKTYPE_D1PCLK1;
  RCC_ClkInitStruct.SYSCLKSource = RCC_SYSCLKSOURCE_PLLCLK;
  RCC_ClkInitStruct.SYSCLKDivider = RCC_SYSCLK_DIV1;
  RCC_ClkInitStruct.AHBCLKDivider = RCC_HCLK_DIV2;
  RCC_ClkInitStruct.APB3CLKDivider = RCC_APB3_DIV2;
  RCC_ClkInitStruct.APB1CLKDivider = RCC_APB1_DIV2;
  RCC_ClkInitStruct.APB2CLKDivider = RCC_APB2_DIV2;
  RCC_ClkInitStruct.APB4CLKDivider = RCC_APB4_DIV2;

  if (HAL_RCC_ClockConfig(&RCC_ClkInitStruct, FLASH_LATENCY_4) != HAL_OK)
  {
    Error_Handler();
  }
}

void PeriphCommonClock_Config(void)
{
  RCC_PeriphCLKInitTypeDef PeriphClkInitStruct = {0};

  /** Initializes the peripherals clock
   */
  PeriphClkInitStruct.PeriphClockSelection = RCC_PERIPHCLK_FMC | RCC_PERIPHCLK_ADC;
  PeriphClkInitStruct.PLL2.PLL2M = 12;
  PeriphClkInitStruct.PLL2.PLL2N = 120;
  PeriphClkInitStruct.PLL2.PLL2P = 4;
  PeriphClkInitStruct.PLL2.PLL2Q = 2;
  PeriphClkInitStruct.PLL2.PLL2R = 1;
  PeriphClkInitStruct.PLL2.PLL2RGE = RCC_PLL2VCIRANGE_1;
  PeriphClkInitStruct.PLL2.PLL2VCOSEL = RCC_PLL2VCOWIDE;
  PeriphClkInitStruct.PLL2.PLL2FRACN = 0;
  PeriphClkInitStruct.FmcClockSelection = RCC_FMCCLKSOURCE_PLL2;
  PeriphClkInitStruct.AdcClockSelection = RCC_ADCCLKSOURCE_PLL2;
  if (HAL_RCCEx_PeriphCLKConfig(&PeriphClkInitStruct) != HAL_OK)
  {
    Error_Handler();
  }
}

/* MPU Configuration */

void MPU_Config(void)
{
  MPU_Region_InitTypeDef MPU_InitStruct = {0};

  /* Disables the MPU */
  HAL_MPU_Disable();

  /** Initializes and configures the Region and the memory to be protected
   */
  MPU_InitStruct.Enable = MPU_REGION_ENABLE;
  MPU_InitStruct.Number = MPU_REGION_NUMBER0;
  MPU_InitStruct.BaseAddress = 0x70000000;
  MPU_InitStruct.Size = MPU_REGION_SIZE_256MB;
  MPU_InitStruct.SubRegionDisable = 0x00;
  MPU_InitStruct.TypeExtField = MPU_TEX_LEVEL0;
  MPU_InitStruct.AccessPermission = MPU_REGION_FULL_ACCESS;
  MPU_InitStruct.DisableExec = MPU_INSTRUCTION_ACCESS_ENABLE;
  MPU_InitStruct.IsShareable = MPU_ACCESS_NOT_SHAREABLE;
  MPU_InitStruct.IsCacheable = MPU_ACCESS_CACHEABLE;
  MPU_InitStruct.IsBufferable = MPU_ACCESS_NOT_BUFFERABLE;

  HAL_MPU_ConfigRegion(&MPU_InitStruct);

  /** Initializes and configures the Region and the memory to be protected
   */
  MPU_InitStruct.Number = MPU_REGION_NUMBER1;
  MPU_InitStruct.BaseAddress = 0x24000000;
  MPU_InitStruct.Size = MPU_REGION_SIZE_1MB;

  HAL_MPU_ConfigRegion(&MPU_InitStruct);
  /* Enables the MPU */
  HAL_MPU_Enable(MPU_PRIVILEGED_DEFAULT);
}

void Error_Handler(void)
{
  __disable_irq();
  while (1)
  {
  }
}
